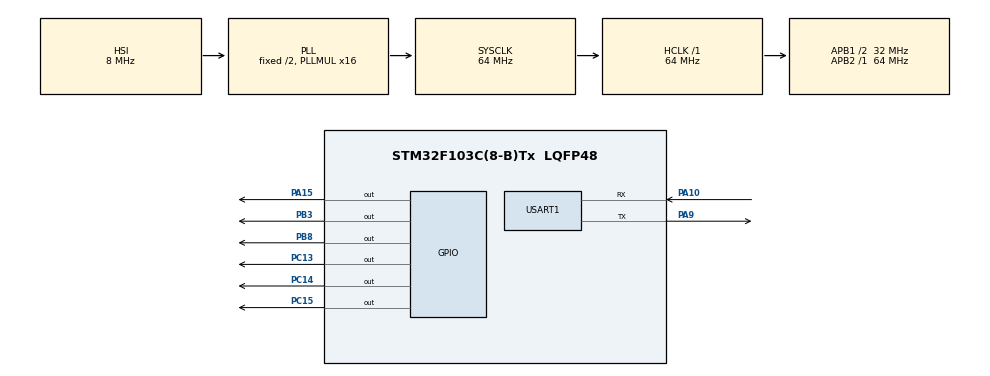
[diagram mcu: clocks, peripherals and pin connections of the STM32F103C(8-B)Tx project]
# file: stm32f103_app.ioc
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Mcu.Family=STM32F1
Mcu.Name=STM32F103C(8-B)Tx
Mcu.Package=LQFP48
NVIC.PriorityGroup=NVIC_PRIORITYGROUP_4
PA10.Mode=Asynchronous
PA10.Signal=USART1_RX
PA13.Mode=Serial_Wire
PA13.Signal=SYS_JTMS-SWDIO
PA14.Mode=Serial_Wire
PA14.Signal=SYS_JTCK-SWCLK
PA15.Signal=GPIO_Output
PA9.Mode=Asynchronous
PA9.Signal=USART1_TX
PB3.Signal=GPIO_Output
PB8.Signal=GPIO_Output
PC13-TAMPER-RTC.GPIO_PuPd=GPIO_PULLUP
PC13-TAMPER-RTC.Signal=GPIO_Output
PC14-OSC32_IN.GPIO_PuPd=GPIO_PULLUP
PC14-OSC32_IN.Signal=GPIO_Output
PC15-OSC32_OUT.GPIO_PuPd=GPIO_PULLUP
PC15-OSC32_OUT.Signal=GPIO_Output
ProjectManager.HeapSize=0x200
ProjectManager.StackSize=0x400
ProjectManager.TargetToolchain=MDK-ARM V5
RCC.AHBFreq_Value=64000000
RCC.APB1CLKDivider=RCC_HCLK_DIV2
RCC.APB1Freq_Value=32000000
RCC.APB1TimFreq_Value=64000000
RCC.APB2Freq_Value=64000000
RCC.APB2TimFreq_Value=64000000
RCC.HCLKFreq_Value=64000000
RCC.PLLMUL=RCC_PLL_MUL16
RCC.SYSCLKFreq_VALUE=64000000
RCC.SYSCLKSource=RCC_SYSCLKSOURCE_PLLCLK
RCC.USBFreq_Value=64000000
USART1.VirtualMode=VM_ASYNC
board=custom

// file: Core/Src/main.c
/* USER CODE BEGIN Header */
/**
  ******************************************************************************
  * @file           : main.c
  * @brief          : Main program body
  ******************************************************************************
  * @attention
  *
  * <h2><center>&copy; Copyright (c) 2024 STMicroelectronics.
  * All rights reserved.</center></h2>
  *
  * This software component is licensed by ST under BSD 3-Clause license,
  * the "License"; You may not use this file except in compliance with the
  * License. You may obtain a copy of the License at:
  *                        opensource.org/licenses/BSD-3-Clause
  *
  ******************************************************************************
  */
/* USER CODE END Header */
#include "main.h"
#include "usart.h"
#include "gpio.h"
#include "common.h"

void SystemClock_Config(void);

int main(void)
{

  /* MCU Configuration--------------------------------------------------------*/

  /* Reset of all peripherals, Initializes the Flash interface and the Systick. */
  HAL_Init();

  /* Configure the system clock */
  SystemClock_Config();

  /* Initialize all configured peripherals */
  MX_GPIO_Init();
  MX_USART1_UART_Init();

  /* Infinite loop */
  /* USER CODE BEGIN WHILE */
   Serial_PutString("app test start \r\n");
  while (1)
  {
    /* USER CODE END WHILE */

    /* USER CODE BEGIN 3 */
		HAL_GPIO_TogglePin(GPIOC,GPIO_PIN_13);
		HAL_Delay(200);
		HAL_GPIO_TogglePin(GPIOC,GPIO_PIN_14);
		HAL_Delay(200);
		HAL_GPIO_TogglePin(GPIOC,GPIO_PIN_15);
		Serial_PutString("app test start 112 \r\n");
		HAL_Delay(200);
  }
  /* USER CODE END 3 */
}

void SystemClock_Config(void)
{
  RCC_OscInitTypeDef RCC_OscInitStruct = {0};
  RCC_ClkInitTypeDef RCC_ClkInitStruct = {0};

  /** Initializes the RCC Oscillators according to the specified parameters
  * in the RCC_OscInitTypeDef structure.
  */
  RCC_OscInitStruct.OscillatorType = RCC_OSCILLATORTYPE_HSI;
  RCC_OscInitStruct.HSIState = RCC_HSI_ON;
  RCC_OscInitStruct.HSICalibrationValue = RCC_HSICALIBRATION_DEFAULT;
  RCC_OscInitStruct.PLL.PLLState = RCC_PLL_ON;
  RCC_OscInitStruct.PLL.PLLSource = RCC_PLLSOURCE_HSI_DIV2;
  RCC_OscInitStruct.PLL.PLLMUL = RCC_PLL_MUL16;
  if (HAL_RCC_OscConfig(&RCC_OscInitStruct) != HAL_OK)
  {
    Error_Handler();
  }
  /** Initializes the CPU, AHB and APB buses clocks
  */
  RCC_ClkInitStruct.ClockType = RCC_CLOCKTYPE_HCLK|RCC_CLOCKTYPE_SYSCLK
                              |RCC_CLOCKTYPE_PCLK1|RCC_CLOCKTYPE_PCLK2;
  RCC_ClkInitStruct.SYSCLKSource = RCC_SYSCLKSOURCE_PLLCLK;
  RCC_ClkInitStruct.AHBCLKDivider = RCC_SYSCLK_DIV1;
  RCC_ClkInitStruct.APB1CLKDivider = RCC_HCLK_DIV2;
  RCC_ClkInitStruct.APB2CLKDivider = RCC_HCLK_DIV1;

  if (HAL_RCC_ClockConfig(&RCC_ClkInitStruct, FLASH_LATENCY_2) != HAL_OK)
  {
    Error_Handler();
  }
}

void Error_Handler(void)
{
  __disable_irq();
  while (1)
  {
  }
}

/************************ (C) COPYRIGHT STMicroelectronics *****END OF FILE****/
